# ISD91200B_v1 register map
File version: 1.0
Registers are 32-bit, read-write, reset 0x0 unless marked. A register's access mark holds for its fields unless they carry their own. Offsets are from the block's base; [hi:lo] are bit positions; 'fields as' and 'values as' point back to an identical list.

## INT — INT Register Map
Base 0x50000300
0x00 IRQ0_SRC ro reset not defined — IRQ0 (BOD) Interrupt Source Identity Register
  [2:0] INT_SRC — Interrupt Source Identity. Bit2: 0. Bit1: 0. Bit0: BOD_INT
0x04 IRQ1_SRC ro reset not defined — IRQ1 (WDT) Interrupt Source Identity Register
  [2:0] INT_SRC — Interrupt Source Identity. Bit2: 0. Bit1: 0. Bit0: WDT_INT
0x08 IRQ2_SRC ro reset not defined — IRQ2 (EINT0) Interrupt Source Identity Register
  [2:0] INT_SRC — Interrupt Source Identity. Bit2: 0. Bit1: 0. Bit0: INT0_INT
0x0C IRQ3_SRC ro reset not defined — IRQ3 (EINT1) Interrupt Source Identity Register
  fields as IRQ2_SRC
0x10 IRQ4_SRC ro reset not defined — IRQ4 (GPA/B) Interrupt Source Identity Register
  [2:0] INT_SRC — Interrupt Source Identity. Bit2: 0. Bit1: GPB_INT. Bit0: GPA_INT
0x14 IRQ5_SRC ro reset not defined — IRQ5 (ALC) Interrupt Source Identity Register
  [2:0] INT_SRC — Interrupt Source Identity. Bit2: 0. Bit1: 0. Bit0: ALC_INT
0x18 IRQ6_SRC ro reset not defined — IRQ6 (PWM0) Interrupt Source Identity Register
  [2:0] INT_SRC — Interrupt Source Identity. Bit2: 0. Bit1: 0. Bit0: PWM_INT
0x1C IRQ7_SRC ro reset not defined — IRQ7 (Reserved) Interrupt Source Identity Register
0x20 IRQ8_SRC ro reset not defined — IRQ8 (TMR0) Interrupt Source Identity Register
  [2:0] INT_SRC — Interrupt Source Identity. Bit2: 0. Bit1: 0. Bit0: TMR0_INT
0x24 IRQ9_SRC ro reset not defined — IRQ9 (TMR1) Interrupt Source Identity Register
  [2:0] INT_SRC — Interrupt Source Identity. Bit2: 0. Bit1: 0. Bit0: TMR1_INT
0x28 IRQ10_SRC ro reset not defined — IRQ10 (Reserved) Interrupt Source Identity Register
0x2C IRQ11_SRC ro reset not defined — IRQ11 (UART1) Interrupt Source Identity Register
  [2:0] INTSRC — Interrupt Source Identity. Bit2: 0. Bit1: 0. Bit0: UART1 INT
0x30 IRQ12_SRC ro reset not defined — IRQ12 (UART0) Interrupt Source Identity Register
  [2:0] INT_SRC — Interrupt Source Identity. Bit2: 0. Bit1: 0. Bit0: UART0_INT
0x34 IRQ13_SRC ro reset not defined — IRQ13 (SPI1) Interrupt Source Identity Register
  [2:0] INT_SRC — Interrupt Source Identity. Bit2: 0. Bit1: 0. Bit0: SPI1 INT
0x38 IRQ14_SRC ro reset not defined — IRQ14 (SPI0) Interrupt Source Identity Register
  [2:0] INT_SRC — Interrupt Source Identity. Bit2: 0. Bit1: 0. Bit0: SPI0_INT
0x3C IRQ15_SRC ro reset not defined — IRQ15 (DPWM) Interrupt Source Identity Register
  [2:0] INT_SRC — Interrupt Source Identity. Bit2: 0. Bit1: Bit0: DPWM INT
0x40 IRQ16_SRC ro reset not defined — IRQ16 (Reserved) Interrupt Source Identity Register
0x44 IRQ17_SRC ro reset not defined — IRQ17 (Reserved) Interrupt Source Identity Register
0x48 IRQ18_SRC ro reset not defined — IRQ18 (I2C0) Interrupt Source Identity Register
  [2:0] INT_SRC — Interrupt Source Identity. Bit2: 0. Bit1: 0. Bit0: I2C0_INT
0x4C IRQ19_SRC ro reset not defined — IRQ19 (Reserved) Interrupt Source Identity Register
0x50 IRQ20_SRC ro reset not defined — IRQ20 (Reserved) Interrupt Source Identity Register
0x54 IRQ21_SRC ro reset not defined — IRQ21 (CMP) Interrupt Source Identity Register
  [2:0] INT_SRC — Interrupt Source Identity. Bit2: 0. Bit1: 0. Bit0: CMP INT
0x58 IRQ22_SRC ro reset not defined — IRQ22 (MAC ) Interrupt Source Identity Register
  [2:0] INT_SRC — Interrupt Source Identity. Bit2: 0. Bit1: 0. Bit0: MAC INT
0x5C IRQ23_SRC ro reset not defined — IRQ23 (Reserved) Interrupt Source Identity Register
0x60 IRQ24_SRC ro reset not defined — IRQ24 (Reserved) Interrupt Source Identity Register
0x64 IRQ25_SRC ro reset not defined — IRQ25 (SARADC) Interrupt Source Identity Register
  [2:0] INT_SRC — Interrupt Source Identity. Bit2: 0. Bit1: 0. Bit0: SARADC INT
0x68 IRQ26_SRC ro reset not defined — IRQ26 (PDMA) Interrupt Source Identity Register
  [2:0] INT_SRC — Interrupt Source Identity. Bit2: 0. Bit1: 0. Bit0: PDMA_INT
0x6C IRQ27_SRC ro reset not defined — IRQ27 (I2S0) Interrupt Source Identity Register
  [2:0] INT_SRC — Interrupt Source Identity. Bit2: 0. Bit1: 0. Bit0: I2S_INT
0x70 IRQ28_SRC ro reset not defined — IRQ28 (CAPS) Interrupt Source Identity Register
  [2:0] INT_SRC — Interrupt Source Identity. Bit2: 0. Bit1: 0. Bit0: CAPS_INT
0x74 IRQ29_SRC ro reset not defined — IRQ29 (ADC) Interrupt Source Identity Register
  [2:0] INT_SRC — Interrupt Source Identity. Bit2: 0. Bit1: 0. Bit0: ADC_INT
0x78 IRQ30_SRC ro reset not defined — IRQ30 (Reserved) Interrupt Source Identity Register
0x7C IRQ31_SRC ro reset not defined — IRQ31 (RTC) Interrupt Source Identity Register
  [2:0] INT_SRC — Interrupt Source Identity. Bit2: 0. Bit1: 0. Bit0: RTC_INT
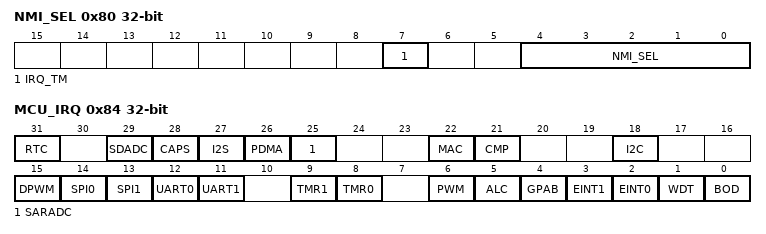
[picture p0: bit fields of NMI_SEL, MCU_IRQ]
0x80 NMI_SEL — NMI Source Interrupt Select Control Register
  [7] IRQ_TM — IRQ Test Mode. If set to 1 then peripheral IRQ signals (0-31) are replaced by the value in the MCU_IRQ register. This is a protected register to program first issue the unlock sequence.
  [4:0] NMI_SEL — NMI Source Interrupt Select. The NMI interrupt to Cortex-M0 can be selected from one of the interrupt[31:0]. The NMI_SEL bit[4:0] used to select the NMI interrupt source
0x84 MCU_IRQ — MCU IRQ Number Identify Register
  [31] RTC — IRQ31 (RTC) Interrupt Source Identity Register. 0: No effect. 1: clear the interrupt
  [29] SDADC — IRQ29 (SDADC) Interrupt Source Identity Register. 0: No effect. 1: clear the interrupt
  [28] CAPS — IRQ28 (CAPS) Interrupt Source Identity Register. 0: No effect. 1: clear the interrupt
  [27] I2S — IRQ27 (I2S0) Interrupt Source Identity Register. 0: No effect. 1: clear the interrupt
  [26] PDMA — IRQ26 (PDMA) Interrupt Source Identity Register. 0: No effect. 1: clear the interrupt
  [25] SARADC — IRQ25 (SARADC) Interrupt Source Identity Register. 0: No effect. 1: clear the interrupt
  [22] MAC — IRQ22 (MAC ) Interrupt Source Identity Register. 0: No effect. 1: clear the interrupt
  [21] CMP — IRQ21 (CMP) Interrupt Source Identity Register. 0: No effect. 1: clear the interrupt
  [18] I2C — IRQ18 (I2C0) Interrupt Source Identity Register. 0: No effect. 1: clear the interrupt
  [15] DPWM — IRQ15 (DPWM) Interrupt Source Identity Register. 0: No effect. 1: clear the interrupt
  [14] SPI0 — IRQ14 (SPI0) Interrupt Source Identity Register. 0: No effect. 1: clear the interrupt
  [13] SPI1 — IRQ13 (SPI1) Interrupt Source Identity Register. 0: No effect. 1: clear the interrupt
  [12] UART0 — IRQ12 (UART0) Interrupt Source Identity Register. 0: No effect. 1: clear the interrupt
  [11] UART1 — IRQ11 (UART1) Interrupt Source Identity Register. 0: No effect. 1: clear the interrupt
  [9] TMR1 — RQ9 (TMR1) Interrupt Source Identity Register. 0: No effect. 1: clear the interrupt
  [8] TMR0 — IRQ8 (TMR0) Interrupt Source Identity Register. 0: No effect. 1: clear the interrupt
  [6] PWM — IRQ6 (PWM0) Interrupt Source Identity Register. 0: No effect. 1: clear the interrupt
  [5] ALC — IRQ5 (ALC) Interrupt Source Identity Register. 0: No effect. 1: clear the interrupt
  [4] GPAB — IRQ4 (GPA/B) Interrupt Source Identity Register. 0: No effect. 1: clear the interrupt
  [3] EINT1 — IRQ3 (EINT1) Interrupt Source Identity Register. 0: No effect. 1: clear the interrupt
  [2] EINT0 — IRQ2 (EINT0) Interrupt Source Identity Register. 0: No effect. 1: clear the interrupt
  [1] WDT — IRQ1 (WDT) Interrupt Source Identity Register. 0: No effect. 1: clear the interrupt
  [0] BOD — IRQ0 (BOD) Interrupt Source Identity Register. 0: No effect. 1: clear the interrupt
